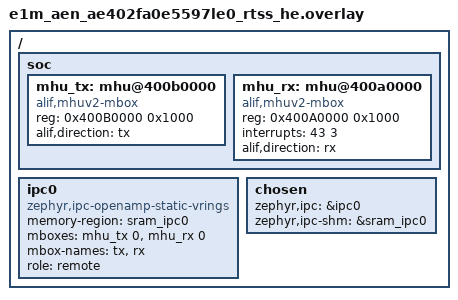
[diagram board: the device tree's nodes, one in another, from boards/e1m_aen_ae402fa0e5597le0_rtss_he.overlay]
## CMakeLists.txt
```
#
# Copyright 2026 Alp Lab AB
#
# SPDX-License-Identifier: Apache-2.0
#
# dualcore_remote -- IPC-service RPMsg REMOTE demo. Its role runs on
# whichever M55 cluster is NOT the resident ATOC's boot-first cluster (see
# docs/BENCH-DUALCORE.md section 0) -- this app builds for both the rtss_hp
# and rtss_he board qualifiers, see boards/*.overlay. Its counterpart,
# dualcore_host, is the RPMsg HOST and lives in ../dualcore_host. Build each
# independently and flash both to the board's split MRAM partitions (see
# boards/alp/e1m_aen for the layout).
#

cmake_minimum_required(VERSION 3.20.0)

find_package(Zephyr REQUIRED HINTS $ENV{ZEPHYR_BASE})
project(dualcore_remote)

target_sources(app PRIVATE src/main.c)
```

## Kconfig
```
# SPDX-License-Identifier: Apache-2.0
# Copyright 2026 Alp Lab AB
#
# App-level Kconfig for dualcore_remote. Presence of this file makes CMake's
# kconfig.cmake use IT as KCONFIG_ROOT instead of $ZEPHYR_BASE/Kconfig (see
# cmake/modules/kconfig.cmake in the Zephyr tree), so the trailing
# `source "Kconfig.zephyr"` below is mandatory -- without it this app would
# lose every upstream Kconfig option (LOG, IPC_SERVICE, MBOX, ...) that
# prj.conf already turns on. This mirrors ../dualcore_host/Kconfig's own
# comment for the identical reason.

config DEMO_REMOTE_BEACON
	bool "Write a liveness beacon to global SRAM0 (bench diagnostic)"
	default n
	help
	  DIAGNOSTIC ONLY -- OFF by default, not part of the shipped image.
	  Enable explicitly with `-DEXTRA_CONF_FILE=beacon.conf` (../beacon.conf),
	  the same opt-in shape dualcore_host's breadcrumb.conf uses; do not flip
	  this default instead.

	  WHY THIS EXISTS: the host's own console (see ../dualcore_host/src/main.c)
	  can prove it completed the SE core-release call, but has no way to prove
	  whether the RELEASED core (this app) ever actually ran -- the two
	  M55 clusters' local memories are not cross-readable from a debug-AP
	  session attached to the other core. A "no PONG, endpoint never binds"
	  symptom is consistent with at least three different failures (the
	  remote never executed at all; it ran but hung before opening ipc0; it
	  opened ipc0 fine but the RPMsg bind itself is broken, e.g. by cache
	  incoherency on the shared vring memory) that all look identical from
	  the host's side alone. This beacon is the observable that tells them
	  apart, by writing to global SRAM0 -- memory reachable from EITHER
	  core's debug-AP, unlike this core's own DTCM.

	  When enabled, src/main.c writes six fixed 32-bit words to global SRAM0
	  at 0x02000100-0x02000114 -- see the top-of-file comment above
	  beacon_write() in src/main.c for exactly which word means what and why
	  each address was picked. This range is deliberately DISJOINT from
	  dualcore_host's own execution-breadcrumb block (0x02000000-0x02000038,
	  see ../dualcore_host/Kconfig's CONFIG_DEMO_EXECUTION_BREADCRUMB) so a
	  bench read of global SRAM0 can never confuse the two apps' diagnostics,
	  even when both are enabled on the same silicon at once (host on one
	  cluster, remote on the other, sharing the same physical SRAM0).

source "Kconfig.zephyr"
```

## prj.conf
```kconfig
# dualcore_remote -- RPMsg REMOTE. Builds for both the rtss_hp and rtss_he
# board qualifiers (see boards/*.overlay); which physical M55 cluster -- and
# so which console -- this image actually runs on depends on the board
# target passed to `west build`, not on anything in this app. See
# docs/BENCH-DUALCORE.md section 0 for which qualifier is bench-proven on
# which SoC, and the root README.md's console-assignment table for the
# per-target UART.
#
# CONFIG_MBOX / CONFIG_MBOX_ALIF_MHUV2 wire in the out-of-tree alif_mhuv2
# module (modules/alif-mhuv2) that backs the mhu_tx/mhu_rx nodes.
# CONFIG_IPC_SERVICE + CONFIG_IPC_SERVICE_BACKEND_RPMSG select the RPMsg
# static-vrings backend, matching the "zephyr,ipc-openamp-static-vrings"
# ipc0 node in the board overlay. CONFIG_OPENAMP is the backend's own
# dependency (see zephyr/samples/subsys/ipc/ipc_service/static_vrings/prj.conf).
CONFIG_MBOX=y
CONFIG_MBOX_ALIF_MHUV2=y
CONFIG_IPC_SERVICE=y
CONFIG_IPC_SERVICE_BACKEND_RPMSG=y
CONFIG_OPENAMP=y

CONFIG_LOG=y
CONFIG_LOG_MODE_IMMEDIATE=y

CONFIG_SERIAL=y
CONFIG_CONSOLE=y
CONFIG_UART_CONSOLE=y

CONFIG_MAIN_STACK_SIZE=2048
CONFIG_HEAP_MEM_POOL_SIZE=4096
```

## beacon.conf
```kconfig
# SPDX-FileCopyrightText: Copyright 2026 Alp Lab AB
# SPDX-License-Identifier: Apache-2.0
#
# Optional bench diagnostic, NOT applied by default -- see ../Kconfig's
# CONFIG_DEMO_REMOTE_BEACON help text and src/main.c's top-of-file comment
# above beacon_write() for what this turns on and how to read the result off
# a memory dump. Pass this fragment explicitly:
#
#   west build ... apps/dualcore_remote -- -DEXTRA_CONF_FILE=beacon.conf
#
# Combine with coherent.conf (the R2 hypothesis fragment) with a
# semicolon-separated list if wanted:
#
#   west build ... apps/dualcore_remote -- -DEXTRA_CONF_FILE="beacon.conf;coherent.conf"
CONFIG_DEMO_REMOTE_BEACON=y
```

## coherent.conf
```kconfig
# SPDX-FileCopyrightText: Copyright 2026 Alp Lab AB
# SPDX-License-Identifier: Apache-2.0
#
# R2 hypothesis fragment: "the remote is up but the RPMsg bind never
# completes because the shared vring memory is cache-incoherent between the
# two M55 D-caches". Pass alongside beacon.conf:
#
#   west build ... apps/dualcore_remote -- -DEXTRA_CONF_FILE="beacon.conf;coherent.conf"
#
# THE NARROW FORM (mark only the shared vring/IPC region non-cacheable) WAS
# ALREADY IN PLACE BEFORE THIS FILE WAS WRITTEN -- it is not added here,
# because there is nothing left to add:
#
#   - boards/alp/e1m_aen/e1m_aen_*_rtss_{hp,he}.dts already tags the ipc0
#     backend's shared carve-out (&sram_ipc0, 0x02010000/64 KB -- the same
#     node both dualcore_host's and dualcore_remote's ipc0 overlays point
#     `memory-region` and `zephyr,ipc-shm` at) with
#     `zephyr,memory-attr = <(DT_MEM_ARM(ATTR_MPU_RAM_NOCACHE))>`.
#   - every e1m_aen board's *_defconfig already sets CONFIG_ARM_MPU=y (for
#     CONFIG_HW_STACK_PROTECTION), and subsys/mem_mgmt/Kconfig defaults
#     CONFIG_MEM_ATTR to y whenever CONFIG_ARM_MPU is y -- CONFIG_MEM_ATTR is
#     the option that turns a `zephyr,memory-attr` DT tag into an ACTUAL
#     programmed MPU region (arch/arm/core/mpu/arm_mpu.c:
#     mpu_configure_regions_from_dt(), gated on `#ifdef CONFIG_MEM_ATTR`) --
#     without it the tag is DT-only metadata with no runtime effect, which is
#     exactly the trap this whole investigation started from on the host
#     side (a `zephyr,memory-attr` on a region nobody ever turned into an MPU
#     region). Confirmed CONFIG_MEM_ATTR=y in a plain build of this app with
#     no fragments applied.
#   - Verified in a REAL LINKED BUILD of e1m_aen/ae822fa0e5597ls0/rtss_hp
#     (2026-07-31, no fragments applied -- i.e. R1's own build), not just
#     read off the DT source: the linked zephyr.elf's `mem_attr_region[]`
#     table (subsys/mem_mgmt/mem_attr.c) holds exactly two DT-tagged
#     entries -- PERIPHERALS (device) and SRAM_IPC0 (dt_addr=0x02010000,
#     dt_size=0x00010000, dt_attr=0x00200000 == DT_MEM_ARM_MPU_RAM_NOCACHE)
#     -- and the total static MPU region count (FLASH_0 + SRAM_0 from
#     arch/arm/core/mpu/arm_mpu_regions.c, plus these two from DT) is 4,
#     nowhere near this core's PMSAv8 region budget. That headroom matters
#     because CONFIG_ASSERT is OFF in this build (`# CONFIG_ASSERT is not
#     set`): arm_core_mpu_configure_static_mpu_regions() only reports a
#     region-table overflow via `__ASSERT(0, ...)`, which compiles to nothing
#     when ASSERT is off -- an overflow here would fail SILENTLY, not abort.
#     Checked that this is NOT happening (region count well under budget), so
#     the SRAM_IPC0 nocache region really is being programmed, not silently
#     dropped.
#
# So the shared vring/IPC memory is ALREADY MPU-non-cacheable on R1 too --
# the narrow form has no further code to change. R2's actual, meaningful
# delta from R1 is therefore the documented FALLBACK: CONFIG_DCACHE=n for
# the whole remote image. This is broader than the narrow form would have
# been (it also stops caching this core's DTCM globals/heap/stack, and the
# beacon words themselves before their explicit sys_cache_data_flush_range()
# calls), but it is what is left to try once the narrow form turns out to
# already be a no-op here -- see this app's README.md / the dispatch report
# this file was written against for what a difference (or lack of one)
# between R1 and R2 on the bench would and would not prove, given the above.
CONFIG_DCACHE=n
```

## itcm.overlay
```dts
/*
 * SPDX-FileCopyrightText: Copyright 2026 Alp Lab AB
 * SPDX-License-Identifier: Apache-2.0
 *
 * Retarget this app from MRAM-XIP to ITCM, so a debugger can place the
 * image directly at the core's local 0x00000000 without going through the
 * MRAM/ATOC path. Used by docs/BENCH-DUALCORE.md's Flow C procedure:
 *
 *     west build ... -DDTC_OVERLAY_FILE=itcm.overlay
 *
 * Use the path-ref `&itcm` form, NOT the phandle-array `<&itcm>` form. The
 * phandle-array form parses, but yields FLASH_SIZE=0 in the generated
 * devicetree, which then overflows the linker script -- the image has
 * nowhere to link. This form is the one that actually builds.
 */

/ {
	chosen {
		zephyr,flash = &itcm;
		/delete-property/ zephyr,code-partition;
	};
};
```

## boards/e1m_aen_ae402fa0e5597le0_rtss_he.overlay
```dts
/*
 * Copyright 2026 Alp Lab AB
 *
 * SPDX-License-Identifier: Apache-2.0
 *
 * dualcore_remote overlay for e1m_aen/ae402fa0e5597le0/rtss_he.
 *
 * NOT BENCH-PROVEN on this SoC (nor is remote->rtss_hp -- see the sibling
 * ../e1m_aen_ae402fa0e5597le0_rtss_hp.overlay). The E1M-AEN401 /
 * ae402fa0e5597le0 (Alif Ensemble E4) resident ATOC's boot-cluster choice
 * has never been observed on real silicon; both mappings are kept
 * buildable for this SoC.
 *
 * mhu_tx / mhu_rx: the Alif MHUv2 mailbox pair this cluster uses to signal
 * the rtss_hp cluster. Each M55 core sees its own TX/RX frame at the SAME
 * register addresses (0x400B0000 / 0x400A0000) -- that is why this overlay
 * is byte-for-byte identical to the ae822fa0e5597ls0 one and to the mhu
 * nodes in dualcore_host's overlays; only the ipc0 "role" property differs
 * between REMOTE (here) and HOST (dualcore_host).
 *
 * interrupts = <43 3> on mhu_rx: GIC IRQ 43 / priority 3 for this MHUv2 RX
 * frame. Not re-derived here -- carried over verbatim from the canonical
 * hardware spec this project was built against; see modules/alif-mhuv2 for
 * the driver that consumes it.
 */

/ {
	soc {
		mhu_tx: mhu@400b0000 {
			compatible = "alif,mhuv2-mbox";
			reg = <0x400B0000 0x1000>;
			alif,direction = "tx";
			#mbox-cells = <1>;
			status = "okay";
		};

		mhu_rx: mhu@400a0000 {
			compatible = "alif,mhuv2-mbox";
			reg = <0x400A0000 0x1000>;
			interrupts = <43 3>;
			alif,direction = "rx";
			#mbox-cells = <1>;
			status = "okay";
		};
	};

	/*
	 * role = "remote": this is the rtss_he (secondary) side of the RPMsg
	 * link. The dualcore_host overlays set role = "host" for the matching
	 * ipc0 node on rtss_hp. memory-region points at the sram_ipc0
	 * carve-out declared once in the board .dts (shared, non-cacheable
	 * SRAM0) -- same physical region both cores' overlays reference.
	 */
	ipc0: ipc0 {
		compatible = "zephyr,ipc-openamp-static-vrings";
		memory-region = <&sram_ipc0>;
		mboxes = <&mhu_tx 0>, <&mhu_rx 0>;
		mbox-names = "tx", "rx";
		role = "remote";
		status = "okay";
	};

	chosen {
		zephyr,ipc = &ipc0;
		zephyr,ipc-shm = &sram_ipc0;
	};
};
```

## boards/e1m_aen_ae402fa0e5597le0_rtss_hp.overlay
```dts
/*
 * Copyright 2026 Alp Lab AB
 *
 * SPDX-License-Identifier: Apache-2.0
 *
 * dualcore_remote overlay for e1m_aen/ae402fa0e5597le0/rtss_hp.
 *
 * NOT BENCH-PROVEN on this SoC. The E1M-AEN401 / ae402fa0e5597le0 (Alif
 * Ensemble E4) resident ATOC's boot-cluster choice has never been observed
 * -- unlike ae822fa0e5597ls0 (E8), where the bench-resident ATOC is known to
 * release M55-HP as the remote (see docs/BENCH-DUALCORE.md section 0). This
 * overlay exists so BOTH the remote->rtss_hp and remote->rtss_he mappings
 * stay buildable for this SoC; do not assume either one matches this part's
 * actual boot order without checking a real E4 unit first.
 *
 * mhu_tx / mhu_rx: the Alif MHUv2 mailbox pair this cluster uses to signal
 * its peer cluster. Each M55 core sees its own TX/RX frame at the SAME
 * register addresses (0x400B0000 / 0x400A0000) -- that is why this overlay
 * is byte-for-byte identical to the ae822fa0e5597ls0 one and to the mhu
 * nodes in dualcore_host's overlays; only the ipc0 "role" property differs
 * between REMOTE (here) and HOST (dualcore_host).
 *
 * interrupts = <43 3> on mhu_rx: GIC IRQ 43 / priority 3 for this MHUv2 RX
 * frame. Not re-derived here -- carried over verbatim from the canonical
 * hardware spec this project was built against; see modules/alif-mhuv2 for
 * the driver that consumes it.
 */

/ {
	soc {
		mhu_tx: mhu@400b0000 {
			compatible = "alif,mhuv2-mbox";
			reg = <0x400B0000 0x1000>;
			alif,direction = "tx";
			#mbox-cells = <1>;
			status = "okay";
		};

		mhu_rx: mhu@400a0000 {
			compatible = "alif,mhuv2-mbox";
			reg = <0x400A0000 0x1000>;
			interrupts = <43 3>;
			alif,direction = "rx";
			#mbox-cells = <1>;
			status = "okay";
		};
	};

	/*
	 * role = "remote": this cluster is the RPMsg link's remote regardless
	 * of which physical M55 cluster it is built for. dualcore_host's
	 * overlays set role = "host" for the matching ipc0 node on the peer
	 * cluster. memory-region points at the sram_ipc0 carve-out declared
	 * once in the board .dts (shared, non-cacheable SRAM0) -- same physical
	 * region both cores' overlays reference.
	 */
	ipc0: ipc0 {
		compatible = "zephyr,ipc-openamp-static-vrings";
		memory-region = <&sram_ipc0>;
		mboxes = <&mhu_tx 0>, <&mhu_rx 0>;
		mbox-names = "tx", "rx";
		role = "remote";
		status = "okay";
	};

	chosen {
		zephyr,ipc = &ipc0;
		zephyr,ipc-shm = &sram_ipc0;
	};
};
```

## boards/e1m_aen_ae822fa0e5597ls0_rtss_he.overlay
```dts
/*
 * Copyright 2026 Alp Lab AB
 *
 * SPDX-License-Identifier: Apache-2.0
 *
 * dualcore_remote overlay for e1m_aen/ae822fa0e5597ls0/rtss_he.
 *
 * NOT the bench-proven default on this SoC. The bench-resident ATOC on
 * E1M-AEN801 boots M55-HE first and it runs the HOST role (see
 * docs/BENCH-DUALCORE.md section 0), so the bench-proven remote mapping is
 * ../e1m_aen_ae822fa0e5597ls0_rtss_hp.overlay, not this file. This overlay
 * is kept buildable -- scripts/build-all.sh can still target
 * remote->rtss_he explicitly -- but it is not what scripts/build-all.sh
 * builds by default for this SoC.
 *
 * mhu_tx / mhu_rx: the Alif MHUv2 mailbox pair this cluster uses to signal
 * the rtss_hp cluster. Each M55 core sees its own TX/RX frame at the SAME
 * register addresses (0x400B0000 / 0x400A0000) -- that is why this overlay
 * is byte-for-byte identical to the ae402fa0e5597le0 one and to the mhu
 * nodes in dualcore_host's overlays; only the ipc0 "role" property differs
 * between REMOTE (here) and HOST (dualcore_host).
 *
 * interrupts = <43 3> on mhu_rx: GIC IRQ 43 / priority 3 for this MHUv2 RX
 * frame. Not re-derived here -- carried over verbatim from the canonical
 * hardware spec this project was built against; see modules/alif-mhuv2 for
 * the driver that consumes it.
 */

/ {
	soc {
		mhu_tx: mhu@400b0000 {
			compatible = "alif,mhuv2-mbox";
			reg = <0x400B0000 0x1000>;
			alif,direction = "tx";
			#mbox-cells = <1>;
			status = "okay";
		};

		mhu_rx: mhu@400a0000 {
			compatible = "alif,mhuv2-mbox";
			reg = <0x400A0000 0x1000>;
			interrupts = <43 3>;
			alif,direction = "rx";
			#mbox-cells = <1>;
			status = "okay";
		};
	};

	/*
	 * role = "remote": this is the rtss_he (secondary) side of the RPMsg
	 * link. The dualcore_host overlays set role = "host" for the matching
	 * ipc0 node on rtss_hp. memory-region points at the sram_ipc0
	 * carve-out declared once in the board .dts (shared, non-cacheable
	 * SRAM0) -- same physical region both cores' overlays reference.
	 */
	ipc0: ipc0 {
		compatible = "zephyr,ipc-openamp-static-vrings";
		memory-region = <&sram_ipc0>;
		mboxes = <&mhu_tx 0>, <&mhu_rx 0>;
		mbox-names = "tx", "rx";
		role = "remote";
		status = "okay";
	};

	chosen {
		zephyr,ipc = &ipc0;
		zephyr,ipc-shm = &sram_ipc0;
	};
};
```

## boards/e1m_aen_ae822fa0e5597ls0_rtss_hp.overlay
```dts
/*
 * Copyright 2026 Alp Lab AB
 *
 * SPDX-License-Identifier: Apache-2.0
 *
 * dualcore_remote overlay for e1m_aen/ae822fa0e5597ls0/rtss_hp.
 *
 * BENCH-PROVEN DEFAULT for this SoC: the resident ATOC on the E1M-AEN801
 * bench unit boots M55-HE (RTSS-HE) first and releases M55-HP (RTSS-HP) via
 * the host's alif_se_boot_cpu() call, so the RPMsg REMOTE runs here. See
 * docs/BENCH-DUALCORE.md section 0 and scripts/build-all.sh's
 * core_app_dir() for the same mapping applied at the build-script level.
 *
 * mhu_tx / mhu_rx: the Alif MHUv2 mailbox pair this cluster uses to signal
 * its peer cluster (rtss_he, running dualcore_host on this bench mapping).
 * Each M55 core sees its own TX/RX frame at the SAME register addresses
 * (0x400B0000 / 0x400A0000) -- that is why this overlay is byte-for-byte
 * identical to the ae402fa0e5597le0 one and to the mhu nodes in
 * dualcore_host's overlays; only the ipc0 "role" property differs between
 * REMOTE (here) and HOST (dualcore_host).
 *
 * interrupts = <43 3> on mhu_rx: GIC IRQ 43 / priority 3 for this MHUv2 RX
 * frame. Not re-derived here -- carried over verbatim from the canonical
 * hardware spec this project was built against; see modules/alif-mhuv2 for
 * the driver that consumes it.
 */

/ {
	soc {
		mhu_tx: mhu@400b0000 {
			compatible = "alif,mhuv2-mbox";
			reg = <0x400B0000 0x1000>;
			alif,direction = "tx";
			#mbox-cells = <1>;
			status = "okay";
		};

		mhu_rx: mhu@400a0000 {
			compatible = "alif,mhuv2-mbox";
			reg = <0x400A0000 0x1000>;
			interrupts = <43 3>;
			alif,direction = "rx";
			#mbox-cells = <1>;
			status = "okay";
		};
	};

	/*
	 * role = "remote": this cluster is the RPMsg link's remote regardless
	 * of which physical M55 cluster it is built for. dualcore_host's
	 * overlays set role = "host" for the matching ipc0 node on the peer
	 * cluster. memory-region points at the sram_ipc0 carve-out declared
	 * once in the board .dts (shared, non-cacheable SRAM0) -- same physical
	 * region both cores' overlays reference.
	 */
	ipc0: ipc0 {
		compatible = "zephyr,ipc-openamp-static-vrings";
		memory-region = <&sram_ipc0>;
		mboxes = <&mhu_tx 0>, <&mhu_rx 0>;
		mbox-names = "tx", "rx";
		role = "remote";
		status = "okay";
	};

	chosen {
		zephyr,ipc = &ipc0;
		zephyr,ipc-shm = &sram_ipc0;
	};
};
```

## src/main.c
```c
/*
 * Copyright 2026 Alp Lab AB
 *
 * SPDX-License-Identifier: Apache-2.0
 *
 * dualcore_remote -- IPC-service RPMsg REMOTE demo for the Alp Lab E1M-AEN
 * SoM (Alif Ensemble E4/E8, ae402fa0e5597le0 / ae822fa0e5597ls0).
 *
 * WHAT THIS DEMONSTRATES: the remote side of the dual-core RPMsg link built
 * in apps/dualcore_host -- see that file's top-of-file comment for the full
 * picture (backend, mailbox driver, MRAM/board layout). This file is
 * intentionally the smaller half: it has no notion of demo cadence, it just
 * answers whatever the host sends.
 *
 * ROLE: this app is the RPMsg "remote" on WHICHEVER M55 cluster it is built
 * for -- see the ipc0 node's role = "remote" property in every
 * boards/e1m_aen_*.overlay in this app. Named by role, not by cluster, for
 * the same reason apps/dualcore_host is -- see that file's ROLE comment.
 * This app builds for both the rtss_hp and rtss_he qualifiers of both SoCs.
 * Its counterpart is apps/dualcore_host, the "host", running on the SAME
 * silicon's OTHER cluster out of the other half of the split MRAM.
 *
 * PROTOCOL: on every received struct ping_pong_msg (a PING), this thread
 * logs it and echoes the identical struct straight back as the PONG -- no
 * sequence-number bookkeeping of its own; the host owns the sequence and
 * detects gaps/reordering on its side.
 *
 * WHY THE SEND HAPPENS IN main()'S THREAD, NOT IN THE RECEIVED CALLBACK:
 * the RPMsg backend invokes .received from its own processing context, and
 * every upstream ipc_service sample (see
 * zephyr/samples/subsys/ipc/ipc_service/BACKEND/remote/src/main.c) defers the
 * reply to a separate thread woken by a semaphore rather than calling
 * ipc_service_send() straight out of that callback. This file follows the
 * same pattern.
 */

#include <string.h>

#include <zephyr/device.h>
#include <zephyr/devicetree.h>
#include <zephyr/ipc/ipc_service.h>
#include <zephyr/kernel.h>
#include <zephyr/logging/log.h>

#ifdef CONFIG_DEMO_REMOTE_BEACON
#include <zephyr/cache.h>
#include <zephyr/init.h>
#endif

LOG_MODULE_REGISTER(dualcore_remote, LOG_LEVEL_INF);

#ifdef CONFIG_DEMO_REMOTE_BEACON
/*
 * --- Liveness beacon (bench diagnostic, NOT shipped) -----------------------
 *
 * Off by default (CONFIG_DEMO_REMOTE_BEACON, see ../Kconfig) -- enabled only
 * with `-DEXTRA_CONF_FILE=beacon.conf` (../beacon.conf), the same opt-in
 * shape dualcore_host's breadcrumb.conf uses. The shipped default image
 * carries none of this.
 *
 * WHY: dualcore_host's console can prove it completed the SE core-release
 * call and that the release entry address (this app's own reset vector)
 * already held plausible-looking code before release -- but it has no way to
 * observe anything on THIS side of that release. This core's own DTCM/ITCM
 * is not reachable from a debug-AP session attached to the host's cluster,
 * so "released but the host never sees a PONG" is consistent with several
 * different failures that all look identical from the host alone: this core
 * never executed; it executed and hung before opening ipc0; it opened ipc0
 * fine but the endpoint bind itself never completes (e.g. because the shared
 * vring memory is cache-incoherent between the two M55 D-caches). This
 * beacon writes to global SRAM0 -- physical memory reachable from EITHER
 * core's debug-AP, unlike this core's own local RAM -- so a bench read can
 * tell those apart without this core's console (which may itself depend on
 * the very thing that is broken) and without a debugger halting this core.
 *
 *   0x02000100 = BEACON_MAGIC, written by the SYS_INIT(EARLY, 0) hook below
 *     -- the earliest C code this build can reach without hand-writing
 *     assembly (see beacon_mark_alive()'s own comment for exactly what
 *     already ran before it). Presence alone proves this core executed at
 *     all -- independent of everything below it.
 *   0x02000104 = BEACON_CORE_ID, written by the same SYS_INIT hook. NOT an
 *     ARM CPUID register read: Cortex-M55 SCB->CPUID reads the same PARTNO
 *     on both RTSS-HP and RTSS-HE (they are the same core RTL instantiated
 *     twice), so it cannot distinguish which cluster wrote a given beacon --
 *     the one thing this word exists to do. Instead this is a
 *     build-time-selected SE-domain CPU-id value (2 = M55_HP, 3 = M55_HE),
 *     the same numbering modules/alif-se-boot/include/alif_se_boot.h's
 *     ALIF_SE_BOOT_CPU_M55_HP/_HE constants use and dualcore_host's Kconfig
 *     (CONFIG_DEMO_RELEASE_PEER_CPU_ID) already reports to the SE for this
 *     same release -- not duplicated by #include, since this app has no
 *     dependency on modules/alif-se-boot (host-only, see ../dualcore_host/
 *     prj.conf), the same reason struct ping_pong_msg below is duplicated
 *     rather than shared.
 *   0x02000108 = BEACON_HEARTBEAT, incremented every
 *     BEACON_HEARTBEAT_PERIOD_MS by a dedicated auto-started thread (see
 *     beacon_heartbeat_thread_entry() below), independent of ipc0's own
 *     state. A single read only proves this core ran ONCE; a re-read some
 *     seconds later that shows this word still advancing is what proves the
 *     core is still alive right now, as opposed to having written the first
 *     three words and then hung or faulted.
 *   0x0200010C = BEACON_PHASE, updated at each RPMsg bring-up milestone in
 *     main() below: BEACON_PHASE_OPEN_DONE after ipc_service_open_instance()
 *     returns, BEACON_PHASE_REGISTER_DONE after
 *     ipc_service_register_endpoint() returns, BEACON_PHASE_BOUND when the
 *     endpoint's own .bound callback fires (ep_bound() below). Read together
 *     with the heartbeat, this is what answers WHERE in the bring-up a stuck
 *     remote actually stopped -- "still alive but stuck between
 *     OPEN_DONE and REGISTER_DONE" and "dead before ever reaching OPEN_DONE"
 *     are indistinguishable from the host's side alone, and look identical
 *     to a "no PONG" timeout either way.
 *   0x02000110 = BEACON_RC_OPEN, the verbatim int return value of
 *     ipc_service_open_instance(), written in the same store as
 *     BEACON_PHASE_OPEN_DONE.
 *   0x02000114 = BEACON_RC_REGISTER, the verbatim int return value of
 *     ipc_service_register_endpoint(), written in the same store as
 *     BEACON_PHASE_REGISTER_DONE.
 *
 * PLACEMENT: 0x02000100-0x02000114 is a DIFFERENT address range from
 * dualcore_host's own execution-breadcrumb block (0x02000000-0x02000038,
 * see ../dualcore_host/Kconfig's CONFIG_DEMO_EXECUTION_BREADCRUMB and
 * ../dualcore_host/src/main.c) -- deliberately, so the two apps' bench
 * diagnostics can never be confused on a read of global SRAM0, even with
 * both enabled at once (host on one cluster, remote on the other, sharing
 * the same physical SRAM0 -- see soc's sram0@2000000, 4 MB). Both ranges sit
 * well below the sram_ipc0 carve-out at 0x02010000 (see the board .dts), so
 * neither can ever collide with the OpenAMP vrings/payload either.
 *
 * CACHE: this SoC family defaults CONFIG_CACHE_MANAGEMENT=y
 * (soc/alif/ensemble/Kconfig.defconfig) and soc_reset_hook() enables the
 * D-cache before any C code in this file runs, so a plain store to global
 * SRAM0 can sit in the D-cache and never reach the physical memory an
 * external SWD probe reads -- the exact defect dualcore_host's own
 * breadcrumb comment describes hunting down on the SE request buffer.
 * Every beacon write below is followed by sys_cache_data_flush_range() for
 * exactly that reason.
 */
#define BEACON_ADDR_MAGIC        ((volatile uint32_t *)0x02000100u)
#define BEACON_ADDR_CORE_ID      ((volatile uint32_t *)0x02000104u)
#define BEACON_ADDR_HEARTBEAT    ((volatile uint32_t *)0x02000108u)
#define BEACON_ADDR_PHASE        ((volatile uint32_t *)0x0200010Cu)
#define BEACON_ADDR_RC_OPEN      ((volatile uint32_t *)0x02000110u)
#define BEACON_ADDR_RC_REGISTER  ((volatile uint32_t *)0x02000114u)

/* Not 0, 0xFFFFFFFF, or a plausible leftover-SRAM value -- unmistakable in a
 * raw hex dump. Deliberately a different bit pattern from dualcore_host's
 * own 0x5A5AxxxxA5-family magics (see that app's src/main.c) so the two
 * apps' beacons are visually distinct too, not just address-disjoint.
 */
#define BEACON_MAGIC 0xC3C33C3Cu

/* SE-domain CPU id, per modules/alif-se-boot/include/alif_se_boot.h's
 * ALIF_SE_BOOT_CPU_M55_HP/_HE constants (2 / 3) -- see the top-of-file
 * comment above for why this, and not an ARM CPUID register read, is what
 * belongs at BEACON_ADDR_CORE_ID. Selected at compile time from the SOC
 * Kconfig symbol this exact board target selects (soc/alif/ensemble/{e4,e8}/
 * Kconfig.soc), covering both SoCs this app builds for.
 */
#if defined(CONFIG_SOC_AE822FA0E5597LS0_RTSS_HP) || defined(CONFIG_SOC_AE402FA0E5597LE0_RTSS_HP)
#define BEACON_CORE_ID 0x00000002u
#elif defined(CONFIG_SOC_AE822FA0E5597LS0_RTSS_HE) || defined(CONFIG_SOC_AE402FA0E5597LE0_RTSS_HE)
#define BEACON_CORE_ID 0x00000003u
#else
#error "unknown RTSS core qualifier -- add it to BEACON_CORE_ID's selection in src/main.c"
#endif

#define BEACON_PHASE_OPEN_DONE     1u
#define BEACON_PHASE_REGISTER_DONE 2u
#define BEACON_PHASE_BOUND         3u

#define BEACON_HEARTBEAT_PERIOD_MS 250
#define BEACON_HEARTBEAT_STACK_SIZE 512
#define BEACON_HEARTBEAT_THREAD_PRIO 7

static void beacon_write(volatile uint32_t *addr, uint32_t value)
{
	*addr = value;
	sys_cache_data_flush_range((void *)addr, sizeof(*addr));
}

/*
 * SYS_INIT(..., EARLY, 0) is the earliest hook this app can reach without
 * hand-writing assembly -- same rationale as dualcore_host's
 * breadcrumb_mark_early() (see that file's comment above its own SYS_INIT
 * call for exactly what already ran before this point on this SoC).
 */
static int beacon_mark_alive(void)
{
	beacon_write(BEACON_ADDR_MAGIC, BEACON_MAGIC);
	beacon_write(BEACON_ADDR_CORE_ID, BEACON_CORE_ID);
	return 0;
}
SYS_INIT(beacon_mark_alive, EARLY, 0);

/*
 * Heartbeat -- a dedicated thread, not a write in main()'s own loop, so it
 * keeps advancing even while main() is blocked inside
 * ipc_service_open_instance() (which does not return on this, the REMOTE,
 * side until the host is up -- see main()'s own comment below) or stuck
 * anywhere else. K_THREAD_DEFINE starts this automatically at kernel init,
 * with no explicit spawn call needed in main().
 */
static void beacon_heartbeat_thread_entry(void *p1, void *p2, void *p3)
{
	uint32_t heartbeat = 0;

	ARG_UNUSED(p1);
	ARG_UNUSED(p2);
	ARG_UNUSED(p3);

	for (;;) {
		beacon_write(BEACON_ADDR_HEARTBEAT, heartbeat);
		heartbeat++;
		k_msleep(BEACON_HEARTBEAT_PERIOD_MS);
	}
}
K_THREAD_DEFINE(beacon_heartbeat_tid, BEACON_HEARTBEAT_STACK_SIZE, beacon_heartbeat_thread_entry,
		 NULL, NULL, NULL, K_PRIO_PREEMPT(BEACON_HEARTBEAT_THREAD_PRIO), 0, 0);
#endif /* CONFIG_DEMO_REMOTE_BEACON */

/* Console node name (e.g. "uart@4901a000"), read straight off the
 * `zephyr,console` chosen node this board target picked -- NEVER a literal
 * UART/core name in this file. A previous version of this banner hardcoded
 * "uart3 (E1M UART1)", which is wrong the moment this image is built for a
 * different board target -- see docs/BENCH-DUALCORE.md for a concrete case:
 * on the bench-proven dual-core run this app's REMOTE logic executed on
 * RTSS-HP, not RTSS-HE.
 */
#define CONSOLE_NODE_NAME DT_NODE_FULL_NAME(DT_CHOSEN(zephyr_console))

/* How long to wait for the endpoint to bind before nagging the log. See
 * dualcore_host/src/main.c for the identical rationale.
 */
#define BOUND_WAIT_S 5

/*
 * Wire format shared with apps/dualcore_host/src/main.c -- both sides MUST
 * agree on this layout; see that file's comment for why it is duplicated
 * rather than shared via a common header.
 */
struct ping_pong_msg {
	uint32_t seq;
};

static K_SEM_DEFINE(bound_sem, 0, 1);

/* Handed from ep_recv() (RPMsg backend's callback context) to main() through
 * ping_msgq below -- NOT through a shared global plus a binary semaphore.
 * A semaphore only serializes the WAKEUP, not the data: with a plain global,
 * a SECOND PING arriving while main() still has an ipc_service_send() for
 * the FIRST one in flight (echoing ping_msg straight back, see main()'s loop
 * below) would overwrite ping_msg out from under that in-flight send,
 * corrupting the echoed PONG -- a real race on a link where the host can
 * outrun this core's echo, not a theoretical one. k_msgq_put()/k_msgq_get()
 * copy the whole struct by value into/out of the queue's own ring buffer, so
 * main() always echoes its own private copy, immune to whatever ep_recv()
 * does after handing it over.
 */
K_MSGQ_DEFINE(ping_msgq, sizeof(struct ping_pong_msg), 1, 4);

static void ep_bound(void *priv)
{
	ARG_UNUSED(priv);
#ifdef CONFIG_DEMO_REMOTE_BEACON
	/* Runs in the RPMsg backend's own callback context, same as ep_recv()
	 * below -- a plain store + cache flush needs no lock either way. See
	 * the top-of-file beacon comment for what BEACON_PHASE_BOUND means.
	 */
	beacon_write(BEACON_ADDR_PHASE, BEACON_PHASE_BOUND);
#endif
	k_sem_give(&bound_sem);
}

static void ep_recv(const void *data, size_t len, void *priv)
{
	struct ping_pong_msg ping;

	ARG_UNUSED(priv);

	if (len != sizeof(ping)) {
		LOG_ERR("PING has unexpected length %zu (expected %zu); dropping", len, sizeof(ping));
		return;
	}

	memcpy(&ping, data, sizeof(ping));

	/* K_NO_WAIT: this callback runs on the RPMsg backend's own context and
	 * must never block. If the queue is still full (main() has not
	 * drained the previous PING yet -- i.e. its echoing
	 * ipc_service_send() for it is still in flight), purge it first so
	 * this newer PING always wins instead of being silently dropped by a
	 * failing k_msgq_put() on a full queue -- k_msgq_purge() cannot fail
	 * on a queue with no waiting receivers, so the retry below is
	 * guaranteed to succeed.
	 */
	if (k_msgq_put(&ping_msgq, &ping, K_NO_WAIT) != 0) {
		k_msgq_purge(&ping_msgq);
		(void)k_msgq_put(&ping_msgq, &ping, K_NO_WAIT);
	}
}

static struct ipc_ept_cfg ep_cfg = {
    .name = "dualcore_ping_pong",
    .cb =
        {
            .bound = ep_bound,
            .received = ep_recv,
        },
};

int main(void)
{
	const struct device *ipc0_instance;
	struct ipc_ept       ep;
	int                  ret;

	/* Banner: names this core and its console from the BUILD, never a
	 * literal -- CONFIG_BOARD_TARGET is Zephyr's own
	 * "<board>/<qualifiers>" string for whatever target this image was
	 * actually configured for, and CONSOLE_NODE_NAME is read off the
	 * `zephyr,console` chosen node above. A previous version of this
	 * banner hardcoded "rtss_he" and "uart3 (E1M UART1)", which lied the
	 * moment this image was built for (or run on, via a debugger, as on
	 * the bench-proven path -- see docs/BENCH-DUALCORE.md) a different
	 * target.
	 */
	LOG_INF("=== Alp Lab E1M-AEN dualcore demo -- REMOTE ===");
	LOG_INF("board target: %s, console: %s", CONFIG_BOARD_TARGET, CONSOLE_NODE_NAME);

	ipc0_instance = DEVICE_DT_GET(DT_NODELABEL(ipc0));

	/*
	 * Log BEFORE opening, because on the remote side this call does not
	 * return until the host is up. The RPMsg static-vrings backend runs
	 * ipc_rpmsg_init() in this thread; for a non-host role that reaches
	 * rpmsg_init_vdev() -> rpmsg_virtio_wait_remote_ready(), an infinite
	 * loop polling the shared-memory virtio status byte for DRIVER_OK and
	 * k_sleep()ing 1 ms per pass. Only the host ever writes DRIVER_OK. So
	 * with no host running, this app parks here forever --
	 * correct standalone behaviour, but indistinguishable from a hang
	 * unless we say so first. Confirmed on E1M-AEN801 silicon: the board
	 * printed the two banner lines and then nothing for 45 s, with the
	 * core healthy in the idle thread (IPSR=0, no fault, no bound-wait
	 * warnings -- because the nag loop further down is never reached).
	 */
	LOG_INF("opening ipc0 as RPMsg remote -- BLOCKS here until the "
	        "host signals virtio DRIVER_OK in shared memory");

	ret = ipc_service_open_instance(ipc0_instance);
#ifdef CONFIG_DEMO_REMOTE_BEACON
	/* See the top-of-file beacon comment for why phase and return code
	 * are written together, immediately after the call returns -- this is
	 * the FIRST thing on this path after the call, before the LOG_ERR
	 * error-handling below, so it captures the outcome even on the error
	 * branch.
	 */
	beacon_write(BEACON_ADDR_RC_OPEN, (uint32_t)ret);
	beacon_write(BEACON_ADDR_PHASE, BEACON_PHASE_OPEN_DONE);
#endif
	if (ret < 0 && ret != -EALREADY) {
		LOG_ERR("ipc_service_open_instance() failed: %d", ret);
		return ret;
	}

	LOG_INF("ipc0 open -- host is alive");

	ret = ipc_service_register_endpoint(ipc0_instance, &ep, &ep_cfg);
#ifdef CONFIG_DEMO_REMOTE_BEACON
	beacon_write(BEACON_ADDR_RC_REGISTER, (uint32_t)ret);
	beacon_write(BEACON_ADDR_PHASE, BEACON_PHASE_REGISTER_DONE);
#endif
	if (ret < 0) {
		LOG_ERR("ipc_service_register_endpoint() failed: %d", ret);
		return ret;
	}

	/* The host may not have registered its endpoint yet -- nag every
	 * BOUND_WAIT_S rather than blocking silently.
	 */
	while (k_sem_take(&bound_sem, K_SECONDS(BOUND_WAIT_S)) != 0) {
		LOG_WRN("endpoint not bound after %d s -- still waiting for the "
		        "host to register its endpoint",
		        BOUND_WAIT_S);
	}
	LOG_INF("endpoint bound; waiting for PING");

	for (;;) {
		struct ping_pong_msg ping;

		k_msgq_get(&ping_msgq, &ping, K_FOREVER);

		LOG_INF("PING seq=%u received; echoing PONG", ping.seq);

		/* ping is this thread's own private copy (k_msgq_get() copied it
		 * out of ping_msgq's ring buffer above) -- a PING arriving while
		 * this send is in flight lands in a NEW queue entry, never in
		 * the memory ipc_service_send() is reading here. See the
		 * top-of-file comment above ping_msgq's definition.
		 */
		ret = ipc_service_send(&ep, &ping, sizeof(ping));
		if (ret < 0) {
			LOG_ERR("ipc_service_send() failed for PONG seq=%u: %d", ping.seq, ret);
		}
	}
}
```
